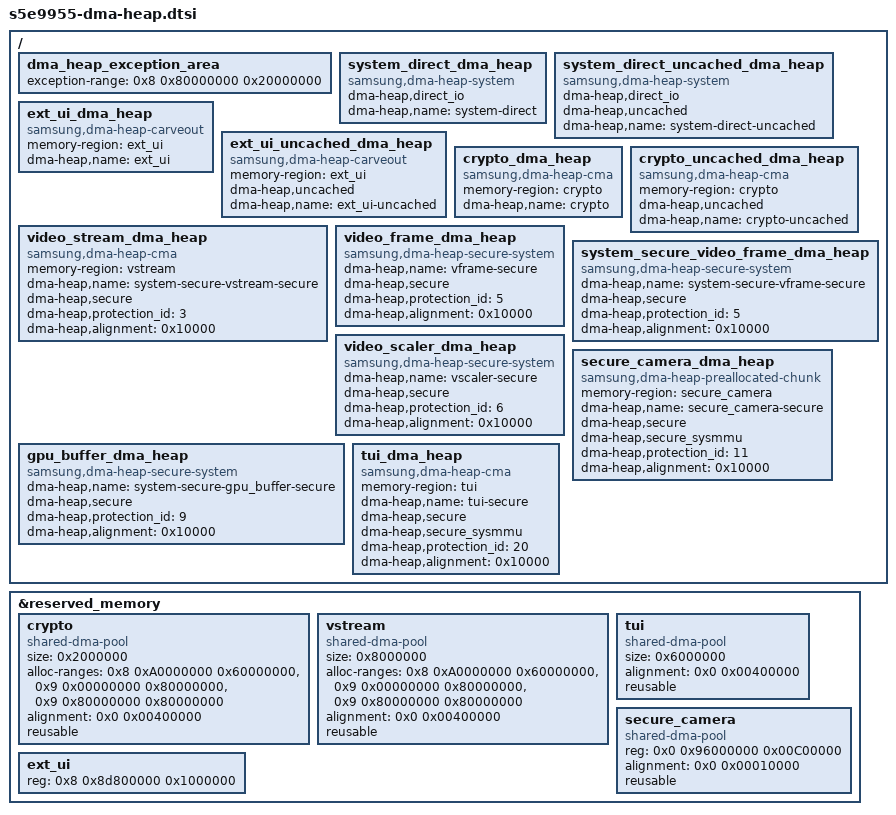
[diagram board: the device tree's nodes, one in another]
// SPDX-License-Identifier: GPL-2.0
/*
 * EXYNOS DMA HEAP device tree source for reserved-memory
 *
 * Copyright (c) 2023 Samsung Electronics Co., Ltd.
 */

/ {
	dma_heap_exception_area {
		#address-cells = <2>;
		#size-cells = <1>;
		ranges;
		exception-range = <0x8 0x80000000 0x20000000>;
	};

	system_direct_dma_heap {
		compatible = "samsung,dma-heap-system";
		dma-heap,direct_io;
		dma-heap,name = "system-direct";
	};

	system_direct_uncached_dma_heap {
		compatible = "samsung,dma-heap-system";
		dma-heap,direct_io;
		dma-heap,uncached;
		dma-heap,name = "system-direct-uncached";
	};

	ext_ui_dma_heap {
		compatible = "samsung,dma-heap-carveout";
		memory-region = <&ext_ui>;
		dma-heap,name = "ext_ui";
	};

	ext_ui_uncached_dma_heap {
		compatible = "samsung,dma-heap-carveout";
		memory-region = <&ext_ui>;
		dma-heap,uncached;
		dma-heap,name = "ext_ui-uncached";
	};

	crypto_dma_heap {
		compatible = "samsung,dma-heap-cma";
		memory-region = <&crypto>;
		dma-heap,name = "crypto";
	};

	crypto_uncached_dma_heap {
		compatible = "samsung,dma-heap-cma";
		memory-region = <&crypto>;
		dma-heap,uncached;
		dma-heap,name = "crypto-uncached";
	};

	video_stream_dma_heap {
		compatible = "samsung,dma-heap-cma";
		memory-region = <&vstream>;
		dma-heap,name = "system-secure-vstream-secure";
		dma-heap,secure;
		dma-heap,protection_id = <3>;
		dma-heap,alignment = <0x10000>;
	};

	video_frame_dma_heap {
		compatible = "samsung,dma-heap-secure-system";
		dma-heap,name = "vframe-secure";
		dma-heap,secure;
		dma-heap,protection_id = <5>;
		dma-heap,alignment = <0x10000>;
	};

	system_secure_video_frame_dma_heap {
		compatible = "samsung,dma-heap-secure-system";
		dma-heap,name = "system-secure-vframe-secure";
		dma-heap,secure;
		dma-heap,protection_id = <5>;
		dma-heap,alignment = <0x10000>;
	};

	video_scaler_dma_heap {
		compatible = "samsung,dma-heap-secure-system";
		dma-heap,name = "vscaler-secure";
		dma-heap,secure;
		dma-heap,protection_id = <6>;
		dma-heap,alignment = <0x10000>;
	};

	gpu_buffer_dma_heap {
		compatible = "samsung,dma-heap-secure-system";
		dma-heap,name = "system-secure-gpu_buffer-secure";
		dma-heap,secure;
		dma-heap,protection_id = <9>;
		dma-heap,alignment = <0x10000>;
	};

	secure_camera_dma_heap {
		compatible = "samsung,dma-heap-preallocated-chunk";
		memory-region = <&secure_camera>;
		dma-heap,name = "secure_camera-secure";
		dma-heap,secure;
		dma-heap,secure_sysmmu;
		dma-heap,protection_id = <11>;
		dma-heap,alignment = <0x10000>;
	};

	tui_dma_heap {
		compatible = "samsung,dma-heap-cma";
		memory-region = <&tui>;
		dma-heap,name = "tui-secure";
		dma-heap,secure;
		dma-heap,secure_sysmmu;
		dma-heap,protection_id = <20>;
		dma-heap,alignment = <0x10000>;
	};
};

&reserved_memory {
	#address-cells = <2>;
	#size-cells = <1>;

	crypto: crypto {
		compatible = "shared-dma-pool";
		size = <0x2000000>;
		alloc-ranges =	<0x8 0xA0000000 0x60000000>,
				<0x9 0x00000000 0x80000000>,
				<0x9 0x80000000 0x80000000>;
		alignment = <0x0 0x00400000>;
		reusable;
	};

	vstream: vstream {
		compatible = "shared-dma-pool";
		size = <0x8000000>;
		alloc-ranges =	<0x8 0xA0000000 0x60000000>,
				<0x9 0x00000000 0x80000000>,
				<0x9 0x80000000 0x80000000>;
		alignment = <0x0 0x00400000>;
		reusable;
	};

	tui: tui {
		compatible = "shared-dma-pool";
		size = <0x6000000>;
		alignment = <0x0 0x00400000>;
		reusable;
	};

	secure_camera: secure_camera {
		compatible = "shared-dma-pool";
		reg = <0x0 0x96000000 0x00C00000>;
		alignment = <0x0 0x00010000>;
		reusable;
	};

	ext_ui: ext_ui {
		reg = <0x8 0x8d800000 0x1000000>;
	};
};
